# MCAN_MCAN_CORE_20701000h register map
Vendor: Texas Instruments
Peripheral module from a debugger description file (folder am62D).
Registers are 32-bit, access not given, reset 0x0 unless marked. A register's access mark holds for its fields unless they carry their own. Offsets are as the file gives them; lines under a group give offsets from that group; [hi:lo] are bit positions; {n}, {i} and the like mark numbered series; 'fields as' and 'values as' point back to an identical list; <NAME> marks a mode.

## mcan_core
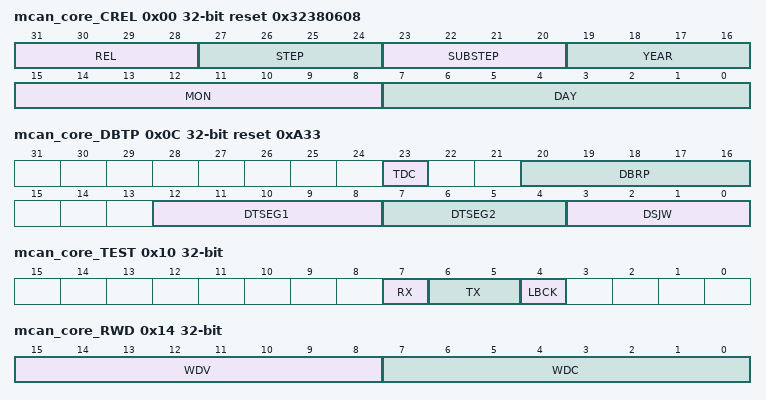
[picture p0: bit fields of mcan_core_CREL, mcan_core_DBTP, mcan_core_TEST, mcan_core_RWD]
0x00 mcan_core_CREL ro reset 0x32380608 — Release dependent constant (version + date)
  [31:28] REL — Core Release One digit, BCD-coded. Reset Source: hsrst_n
  [27:24] STEP — Step of Core Release One digit, BCD-coded. Reset Source: hsrst_n
  [23:20] SUBSTEP — Sub-step of Core Release One digit, BCD-coded. Reset Source: hsrst_n
  [19:16] YEAR — Time Stamp Year One digit, BCD-coded. Reset Source: hsrst_n
  [15:8] MON — Time Stamp Month Two digits, BCD-coded. Reset Source: hsrst_n
  [7:0] DAY — Time Stamp Day Two digits, BCD-coded. Reset Source: hsrst_n
0x04 mcan_core_ENDN ro reset 0x87654321 — Constant '0x8765 4321'
  [31:0] ETV — Endianness Test Value The endianness test value is 8765 4321h. Reset Source: hsrst_n
0x08 mcan_core_CUST reset not defined — Optional customer-specific register
0x0C mcan_core_DBTP rw reset 0xA33 — Configuration of data phase bit timing, transmitter delay compensation enable
  [23] TDC — Transmitter Delay Compensation 0h Transmitter Delay Compensation disabled1h Transmitter Delay Compensation enabled
  [20:16] DBRP — Data Baud Rate Prescaler The value by which the oscillator frequency is divided for generating the bit time quanta. The bit time is built up from a multiple of this quanta. Valid values for the Baud Rate Prescaler are 0 to 31 (0h-1Fh). The actual interpretation by the hardware of this value is such that one more than the value programmed here is used. Reset Source: hsrst_n
  [12:8] DTSEG1 — Data time segment before sample point Valid values are 0 to 31 (0h-1Fh). The actual interpretation by the hardware of this value is such that one more than the programmed value is used. Reset Source: hsrst_n
  [7:4] DTSEG2 — Data time segment after sample point Valid values are 0 to 15 (0h-Fh). The actual interpretation by the hardware of this value is such that one more than the programmed value is used. Reset Source: hsrst_n
  [3:0] DSJW — Data (Re)Synchronization Jump Width Valid values are 0 to 15 (0h-Fh). The actual interpretation by the hardware of this value is such that one more than the value programmed here is used. Reset Source: hsrst_n
0x10 mcan_core_TEST access per field — Test mode selection
  [7] RX ro — Receive Pin Monitors the actual value of the MCAN RX pin 0h The CAN bus is dominant (MCAN RX = 0h)1h The CAN bus is recessive (MCAN RX = 1h)
  [6:5] TX rw — Control of Transmit Pin 0h Reset value, the MCAN TX pin controlled by the CAN Core, updated at the end of the CAN bit time1h Sample Point can be monitored at the MCAN TX pin2h Dominant (0) level at the MCAN TX pin3h Recessive (1) at the MCAN TX pin
  [4] LBCK rw — Loopback Mode 0h Reset value, Loopback Mode is disabled1h Loopback Mode is enabled (see Test Modes)
0x14 mcan_core_RWD access per field — Monitors the READY output of the Message RAM
  [15:8] WDV ro — Watchdog Value Actual Message RAM Watchdog Counter Value. Reset Source: hsrst_n
  [7:0] WDC rw — Watchdog Configuration Start value of the Message RAM Watchdog Counter. With the reset value of 0h the counter is disabled. Reset Source: hsrst_n
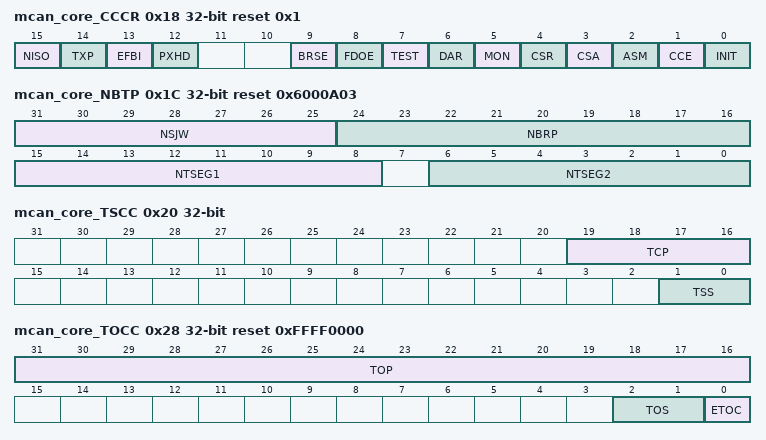
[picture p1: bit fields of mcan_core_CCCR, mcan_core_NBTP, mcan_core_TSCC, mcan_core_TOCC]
0x18 mcan_core_CCCR access per field reset 0x1 — Operation mode configuration
  [15] NISO rw — Non ISO Operation 0h CAN FD frame format according to ISO 11898-1:2015.1h CAN FD frame format according to Bosch CAN FD Specification 1.0.
  [14] TXP rw — Transmit Pause If this bit is set, the MCAN module pauses for two CAN bit times before starting the next transmission after itself has successfully transmitted a frame (see Tx Handling) . 0h Transmit pause disabled1h Transmit pause enabled
  [13] EFBI rw — Edge Filtering during Bus Integration 0h Edge filtering disabled1h Two consecutive dominant tq required to detect an edge for hard synchronization
  [12] PXHD rw — Protocol Exception Handling DisableNote: When protocol exception handling is disabled, the MCAN module will transmit an error frame when it detects a protocol exception condition. 0h Protocol exception handling enabled1h Protocol exception handling disabled
  [9] BRSE rw — Bit Rate Switch EnableNote: When CAN FD operation is disabled the MCAN_CCCR[8] FDOE = 0h 0h Bit rate switching for transmissions disabled1h Bit rate switching for transmissions enabled
  [8] FDOE rw — FD Operation Enable 0h FD operation disabled1h FD operation enabled
  [7] TEST rw — Test Mode Enable 0h Normal operation. The MCAN_TEST register holds reset values.1h Test Mode. Write access to the MCAN_TEST register enabled.
  [6] DAR rw — Disable Automatic Retransmission 0h Automatic retransmission of messages not transmitted successfully enabled1h Automatic retransmission disabled
  [5] MON rw — Bus Monitoring Mode The MCAN_CCCR[5] MON bit can only be set by the Host CPU when both MCAN_CCCR[1] CCE and MCAN_CCCR[0] INIT bits are set to 1. The bit can be reset by the Host CPU at any time. 0h Bus Monitoring Mode is disabled1h Bus Monitoring Mode is enabled
  [4] CSR rw — Clock Stop Request 0h No clock stop is requested1h Clock stop requested. When clock stop is requested, first the MCAN_CCCR[0] INIT bit and then the MCAN_CCCR[3] CSA bit will be set after all pending transfer requests have been completed and the CAN bus reached idle.
  [3] CSA ro — Clock Stop Acknowledge 0h No clock stop acknowledged1h The MCAN module may be set in power down by stopping MCAN interface clock and MCAN functional clock
  [2] ASM rw — Restricted Operation Mode The MCAN_CCCR[2] ASM bit can only be set by the Host CPU when both MCAN_CCCR[1] CCE and MCAN_CCCR[0] INIT bits are set to 1. The bit can be reset by the Host CPU at any time. For a description of the Restricted Operation Mode, see Restricted Operation Mode. 0h Normal CAN operation1h Restricted Operation Mode active
  [1] CCE rw — Configuration Change Enable 0h The Host CPU has no write access to the protected configuration registers1h The Host CPU has write access to the protected configuration registers (while the MCAN_CCCR[0] INIT = 1h)
  [0] INIT rw — InitializationNote: Due to the synchronization mechanism between the two clock domains, there may be a delay until the value written to the MCAN_CCCR[0] INIT bit can be read back. Therefore the software has to assure that the previous value written to the MCAN_CCCR[0] INIT bit has been accepted by Reading the MCAN_CCCR[0] INIT bit before setting the MCAN_CCCR[0] INIT bit to a new value. 0h Normal Operation1h Initialization is started
0x1C mcan_core_NBTP rw reset 0x6000A03 — Configuration of arbitration phase bit timing
  [31:25] NSJW — Nominal (Re)Synchronization Jump Width Valid values are 0 to 127 (0h-7Fh). The actual interpretation by the hardware of this value is such that one more than the value programmed here is used. Reset Source: hsrst_n
  [24:16] NBRP — Nominal Baud Rate Prescaler The value by which the oscillator frequency is divided for generating the bit time quanta. The bit time is built up from a multiple of this quanta. Valid values for the Baud Rate Prescaler are 0 to 511 (0h-1FFh). The actual interpretation by the hardware of this value is such that one more than the value programmed here is used. Reset Source: hsrst_n
  [15:8] NTSEG1 — Nominal Time segment before sample point Valid values are 1 to 255 (1h-FFh). The actual interpretation by the hardware of this value is such that one more than the programmed value is used. Reset Source: hsrst_n
  [6:0] NTSEG2 — Nominal Time segment after sample point Valid values are 0 to 127 (0h-7Fh). The actual interpretation by the hardware of this value is such that one more than the programmed value is used. Note: With a CAN clock (MCAN functional clock) of 8 MHz, the reset value of 0600 0A03h configures the MCAN module for a bit rate of 500 kbit/s. Reset Source: hsrst_n
0x20 mcan_core_TSCC rw — Timestamp counter prescaler setting, selection of internal/external timestamp vector
  [19:16] TCP — Timestamp Counter Prescaler Configures the timestamp and timeout counters time unit in multiples of CAN bit times [1-16 (0h-Fh)]. The actual interpretation by the hardware of this value is such that one more than the value programmed here is used. Note: With CAN FD an external counter is required for timestamp generation (MCAN_TSCC[1-0] TSS = 2h) Reset Source: hsrst_n
  [1:0] TSS — Timestamp Select 0h Timestamp counter value always 0h1h Timestamp counter value incremented according to the MCAN_TSCC[19-16] TCP field2h External timestamp counter value used3h Same as 0h
0x24 mcan_core_TSCV — Read/reset timestamp counter
  [15:0] TSC — Timestamp Counter The internal/external Timestamp Counter value is captured on start of frame (both Rx and Tx). When the MCAN_TSCC[1-0] TSS = 1h, the Timestamp Counter is incremented in multiples of CAN bit times [1-16] depending on the configuration of the MCAN_TSCC[19-16] TCP field. A wrap around sets interrupt flag MCAN_IR[16] TSW. Write access resets the counter to zero. When the MCAN_TSCC[1-0] TSS = 2h, the MCAN_TSCV[15-0] TSC field reflects the external Timestamp Counter value. A write access has no impact. Note: A 'wrap around' is a change of the Timestamp Counter value from non-zero to zero not caused by write access to the MCAN_TSCV register. Reset Source: hsrst_n (access R/WTC)
0x28 mcan_core_TOCC rw reset 0xFFFF0000 — Configuration of timeout period, selection of timeout counter operation mode
  [31:16] TOP — Timeout Period Start value of the Timeout Counter (down-counter). Configures the Timeout Period. Reset Source: hsrst_n
  [2:1] TOS — Timeout Select When operating in Continuous mode, a write to the MCAN_TOCV[15-0] TOC field presets the counter to the value configured by the MCAN_TOCC[31-16] TOP field and continues down-counting. When the Timeout Counter is controlled by one of the FIFOs, an empty FIFO presets the counter to the value configured by the MCAN_TOCC[31-16] TOP field. Down-counting is started when the first FIFO element is stored. 0h Continuous operation1h Timeout controlled by Tx Event FIFO2h Timeout controlled by Rx FIFO 03h Timeout controlled by Rx FIFO 1
  [0] ETOC — Enable Timeout Counter 0h Timeout Counter disabled1h Timeout Counter enabled
0x2C mcan_core_TOCV reset 0xFFFF — Read/reset timeout counter
  [15:0] TOC — Timeout Counter The Timeout Counter is decremented in multiples of CAN bit times [1-16] depending on the configuration of the MCAN_TSCC[19-16] TCP field. When decremented to zero, interrupt flag MCAN_IR[18] TOO is set and the Timeout Counter is stopped. Start and reset/ restart conditions are configured via the MCAN_TOCC[2-1] TOS field. Reset Source: hsrst_n (access R/WTC)
0x30 mcan_core_reserved00 reset not defined — Reserved field
0x34 mcan_core_reserved11 reset not defined — Reserved field
0x38 mcan_core_reserved22 reset not defined — Reserved field
0x3C mcan_core_reserved33 reset not defined — Reserved field
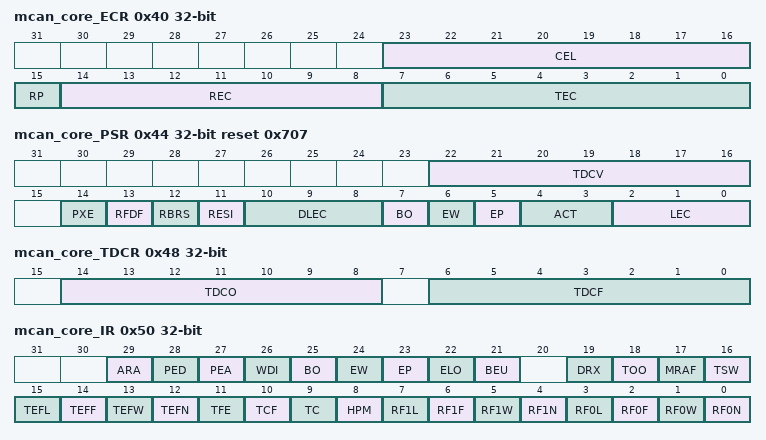
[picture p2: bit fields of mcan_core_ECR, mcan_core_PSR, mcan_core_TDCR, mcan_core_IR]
0x40 mcan_core_ECR ro — State of Rx/Tx Error Counter, CAN Error Logging
  [23:16] CEL — CAN Error Logging The counter is incremented each time when a CAN protocol error causes the Transmit Error Counter or the Receive Error Counter to be incremented. It is reset by read access to the MCAN_ECR[23-16] CEL field. The counter stops at FFh; the next increment of the MCAN_ECR[7-0] TEC or MCAN_ECR[14-8] REC fields sets interrupt flag MCAN_IR[22] ELO. Reset Source: hsrst_n
  [15] RP — Receive Error Passive 0h The Receive Error Counter is below the error passive level of 1281h The Receive Error Counter has reached the error passive level of 128
  [14:8] REC — Receive Error Counter Actual state of the Receive Error Counter, values between 0 and 127. Reset Source: hsrst_n
  [7:0] TEC — Transmit Error Counter Actual state of the Transmit Error Counter, values between 0 and 255. Note: When the MCAN_CCCR[2] ASM bit is set, the CAN protocol controller does not increment the MCAN_ECR[7-0] TEC and MCAN_ECR[14-8] REC fields when a CAN protocol error is detected, but the MCAN_ECR[23-16] CEL field is still incremented. Reset Source: hsrst_n
0x44 mcan_core_PSR ro reset 0x707 — CAN protocol controller status, transmitter delay compensation value
  [22:16] TDCV — Transmitter Delay Compensation Value Position of the secondary sample point, defined by the sum of the measured delay from the MCAN TX to MCAN RX pins and the MCAN_TDCR[14-8] TDCO field. The SSP position is, in the data phase, the number of mtq between the start of the transmitted bit and the secondary sample point. Valid values are 0 to 127 mtq (0h-7Fh). Reset Source: hsrst_n
  [14] PXE — Protocol Exception Event 0h No protocol exception event occurred since last read access1h Protocol exception event occurred
  [13] RFDF — Received a CAN FD Message This bit is set independent of acceptance filtering. 0h Since this bit was reset by the Host CPU, no CAN FD message has been received1h Message in CAN FD format with FDF flag set has been received
  [12] RBRS — BRS flag of last received CAN FD Message This bit is set together with the MCAN_PSR[13] RFDF bit, independent of acceptance filtering. 0h Last received CAN FD message did not have its BRS flag set1h Last received CAN FD message had its BRS flag set
  [11] RESI — ESI flag of last received CAN FD Message This bit is set together with the MCAN_PSR[13] RFDF bit, independent of acceptance filtering. 0h Last received CAN FD message did not have its ESI flag set1h Last received CAN FD message had its ESI flag set
  [10:8] DLEC — Data Phase Last Error Code Type of last error that occurred in the data phase of a CAN FD format frame with its BRS flag set. Coding is the same as for the MCAN_PSR[2-0] LEC field. This field will be cleared to zero when a CAN FD format frame with its BRS flag set has been transferred (reception or transmission) without error. Reset Source: hsrst_n
  [7] BO — Bus_Off Status 0h The MCAN module is not Bus_Off1h The MCAN module is in Bus_Off state
  [6] EW — Warning Status 0h Both error counters are below the Error_Warning limit of 961h At least one of error counter has reached the Error_Warning limit of 96
  [5] EP — Error Passive 0h The MCAN module is in the Error_Active state. It normally takes part in bus communication and sends an active error flag when an error has been detected1h The MCAN module is in the Error_Passive state
  [4:3] ACT — Activity Monitors the module's CAN communication state.Note: ACT is set to 0h by a Protocol Exception Event. 0h Synchronizing - node is synchronizing on CAN communication1h Idle - node is neither receiver nor transmitter2h Receiver - node is operating as receiver3h Transmitter - node is operating as transmitter
  [2:0] LEC — Last Error Code The MCAN_PSR[2-0] LEC field indicates the type of the last error to occur on the CAN bus. This field will be cleared to 0h when a message has been transferred (reception or transmission) without error.Note: When a frame in CAN FD format has reached the data phase with BRS flag set, the next CAN event (error or valid frame) will be shown in the MCAN_PSR[10-8] DLEC field instead of the MCAN_PSR[2-0] LEC field. An error in a fixed stuff bit of a CAN FD CRC sequence will be shown as a Form Error, not Stuff Error. 0h No Error: No error occurred since the MCAN_PSR[2-0] LEC field has been reset by successful reception or transmission.1h Stuff Error: More than 5 equal bits in a sequence have occurred in a part of a received message where this is not allowed.2h Form Error: A fixed format part of a received frame has the wrong format.3h AckError: The message transmitted by the MCAN module was not acknowledged by another node.4h Bit1Error: During the transmission of a message (with the exception of the arbitration field), the device wanted to send a recessive level (bit of logical value 1), but the monitored bus value was dominant.5h Bit0Error: During the transmission of a message (or acknowledge bit, or active error flag, or overload flag), the device wanted to send a dominant level (data or identifier bit logical value 0), but the monitored bus value was recessive. During Bus_Off recovery this status is set each time a sequence of 11 recessive bits has been monitored. This enables the Host CPU to monitor the proceeding of the Bus_Off recovery sequence (indicating the bus is not stuck at dominant or continuously disturbed).6h CRCError: The CRC check sum of a received message was incorrect. The CRC of an incom- ing message does not match with the CRC calculated from the received data.7h NoChange: Any read access to the Protocol Status Register re-initializes the MCAN_PSR[2-0] LEC field to 7h. When the MCAN_PSR[2-0] LEC field shows the value 7h, no CAN bus event was detected since the last Host CPU read access to the Protocol Status Register.
0x48 mcan_core_TDCR rw — configuration of transmitter delay compensation offset and filter window length
  [14:8] TDCO — Transmitter Delay Compensation Offset Offset value defining the distance between the measured delay from the MCAN RX and MCAN TX pins and the secondary sample point. Valid values are 0 to 127 mtq (0h-7Fh). Reset Source: hsrst_n
  [6:0] TDCF — Transmitter Delay Compensation Filter Window Length Defines the minimum value for the SSP position, dominant edges on the MCAN RX pin that would result in an earlier SSP position are ignored for transmitter delay measure-ment. The feature is enabled when the MCAN_TDCR[6-0] TDCF field is configured to a value greater than the MCAN_TDCR[14-8] TDCO field. Valid values are 0 to 127 mtq (0h-7Fh). Reset Source: hsrst_n
0x4C mcan_core_reserved44 reset not defined — Reserved field
0x50 mcan_core_IR — Interrupt flags
  [29] ARA — Access to Reserved Address 0h No access to reserved address occurred1h Access to reserved address occurred (access R/W1TC)
  [28] PED — Protocol Error in Data Phase 0h No protocol error in data phase1h Protocol error in data phase detected (MCAN_PSR[10-8] DLEC != 0.7) (access R/W1TC)
  [27] PEA — Protocol Error in Arbitration Phase 0h No protocol error in arbitration phase1h Protocol error in arbitration phase detected (MCAN_PSR[2-0] LEC != 0.7) (access R/W1TC)
  [26] WDI — Watchdog Interrupt 0h No Message RAM Watchdog event occurred1h Message RAM Watchdog event due to missing READY (access R/W1TC)
  [25] BO — Bus_Off Status 0h Bus_Off status unchanged1h Bus_Off status changed (access R/W1TC)
  [24] EW — Warning Status 0h Error_Warning status unchanged1h Error_Warning status changed (access R/W1TC)
  [23] EP — Error Passive 0h Error_Passive status unchanged1h Error_Passive status changed (access R/W1TC)
  [22] ELO — Error Logging Overflow 0h CAN Error Logging Counter did not overflow1h Overflow of CAN Error Logging Counter occurred (access R/W1TC)
  [21] BEU — Bit Error Uncorrected Message RAM bit error detected, uncorrected. Controlled by input signal generated by parity/ECC logic attached to the Message RAM. An uncorrected Message RAM bit error sets the MCAN_CCCR[0] INIT bit to 1. This is done to avoid transmission of corrupted data. 0h No bit error detected when reading from Message RAM1h Bit error detected, uncorrected (example: parity logic) (access R/W1TC)
  [19] DRX — Message stored to Dedicated Rx Buffer The flag is set whenever a received message has been stored into a dedicated Rx Buffer. 0h No Rx Buffer updated1h At least one received message stored into an Rx Buffer (access R/W1TC)
  [18] TOO — Timeout Occurred 0h No timeout1h Timeout reached (access R/W1TC)
  [17] MRAF — Message RAM Access Failure The flag is set, when the Rx Handler: a) has not completed acceptance filtering or storage of an accepted message until the arbitration field of the following message has been received. In this case acceptance filtering or message storage is aborted and the Rx Handler starts processing of the following message. b) was not able to write a message to the Message RAM. In this case message storage is aborted. In both cases the FIFO put index is not updated respectively the New Data flag for a dedicated Rx Buffer is not set, a partly stored message is overwritten when the next message is stored to this location. The flag is also set when the Tx Handler was not able to read a message from the Message RAM in time. In this case message transmission is aborted. In case of a Tx Handler access failure the MCAN module is switched into Restricted Operation Mode (see Restricted Operation Mode). To leave Restricted Operation Mode, the Host CPU has to reset the MCAN_CCCR[2] ASM bit. 0h No Message RAM access failure occurred1h Message RAM access failure occurred (access R/W1TC)
  [16] TSW — Timestamp Wraparound 0h No timestamp counter wrap-around1h Timestamp counter wrapped around (access R/W1TC)
  [15] TEFL — Tx Event FIFO Element Lost 0h No Tx Event FIFO element lost1h Tx Event FIFO element lost, also set after write attempt to Tx Event FIFO of size zero (access R/W1TC)
  [14] TEFF — Tx Event FIFO Full 0h Tx Event FIFO not full1h Tx Event FIFO full (access R/W1TC)
  [13] TEFW — Tx Event FIFO Watermark Reached 0h Tx Event FIFO fill level below watermark1h Tx Event FIFO fill level reached watermark (access R/W1TC)
  [12] TEFN — Tx Event FIFO New Entry 0h Tx Event FIFO unchanged1h Tx Handler wrote Tx Event FIFO element (access R/W1TC)
  [11] TFE — Tx FIFO Empty 0h Tx FIFO non-empty1h Tx FIFO empty (access R/W1TC)
  [10] TCF — Transmission Cancellation Finished 0h No transmission cancellation finished1h Transmission cancellation finished (access R/W1TC)
  [9] TC — Transmission Completed 0h No transmission completed1h Transmission completed (access R/W1TC)
  [8] HPM — High Priority Message 0h No high priority message received1h High priority message received (access R/W1TC)
  [7] RF1L — Rx FIFO 1 Message Lost 0h No Rx FIFO 1 message lost1h Rx FIFO 1 message lost, also set after write attempt to Rx FIFO 1 of size zero (access R/W1TC)
  [6] RF1F — Rx FIFO 1 Full 0h Rx FIFO 1 not full1h Rx FIFO 1 full (access R/W1TC)
  [5] RF1W — Rx FIFO 1 Watermark Reached 0h Rx FIFO 1 fill level below watermark1h Rx FIFO 1 fill level reached watermark (access R/W1TC)
  [4] RF1N — Rx FIFO 1 New Message 0h No new message written to Rx FIFO 11h New message written to Rx FIFO 1 (access R/W1TC)
  [3] RF0L — Rx FIFO 0 Message Lost 0h No Rx FIFO 0 message lost1h Rx FIFO 0 message lost, also set after write attempt to Rx FIFO 0 of size zero (access R/W1TC)
  [2] RF0F — Rx FIFO 0 Full 0h Rx FIFO 0 not full1h Rx FIFO 0 full (access R/W1TC)
  [1] RF0W — Rx FIFO 0 Watermark Reached 0h Rx FIFO 0 fill level below watermark1h Rx FIFO 0 fill level reached watermark (access R/W1TC)
  [0] RF0N — Rx FIFO 0 New Message 0h No new message written to Rx FIFO 01h New message written to Rx FIFO 0 (access R/W1TC)
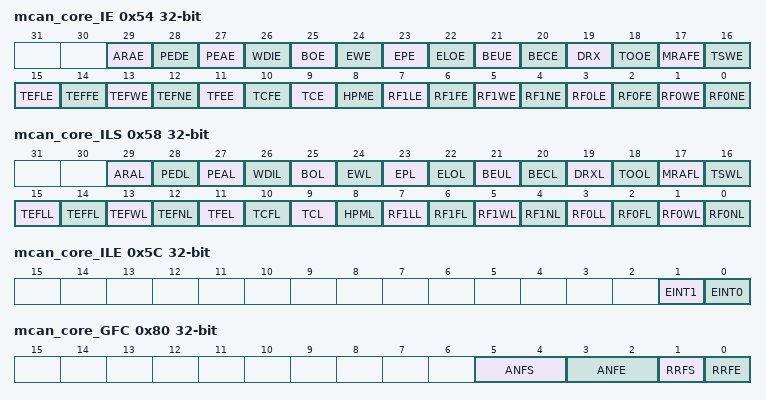
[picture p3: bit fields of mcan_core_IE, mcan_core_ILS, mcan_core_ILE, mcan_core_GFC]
0x54 mcan_core_IE rw — Interrupt enable/disable
  [29] ARAE — Access to Reserved Address Enable 0h Interrupt disabled1h Interrupt enabled
  [28] PEDE — Protocol Error in Data Phase Enable 0h Interrupt disabled1h Interrupt enabled
  [27] PEAE — Protocol Error in Arbitration Phase Enable 0h Interrupt disabled1h Interrupt enabled
  [26] WDIE — Watchdog Interrupt Enable 0h Interrupt disabled1h Interrupt enabled
  [25] BOE — Bus_Off Status Interrupt Enable 0h Interrupt disabled1h Interrupt enabled
  [24] EWE — Warning Status Interrupt Enable 0h Interrupt disabled1h Interrupt enabled
  [23] EPE — Error Passive Interrupt Enable 0h Interrupt disabled1h Interrupt enabled
  [22] ELOE — Error Logging Overflow Interrupt Enable 0h Interrupt disabled1h Interrupt enabled
  [21] BEUE — Bit Error Uncorrected Interrupt Enable 0h Interrupt disabled1h Interrupt enabled
  [20] BECE — Bit Error Corrected Interrupt Enable 0h Interrupt disabled1h Interrupt enabled
  [19] DRX — Message stored to Dedicated Rx Buffer Interrupt Enable Reset Source: hsrst_n
  [18] TOOE — Timeout Occurred Interrupt Enable 0h Interrupt disabled1h Interrupt enabled
  [17] MRAFE — Message RAM Access Failure Interrupt Enable 0h Interrupt disabled1h Interrupt enabled
  [16] TSWE — Timestamp Wraparound Interrupt Enable 0h Interrupt disabled1h Interrupt enabled
  [15] TEFLE — Tx Event FIFO Event Lost Interrupt Enable 0h Interrupt disabled1h Interrupt enabled
  [14] TEFFE — Tx Event FIFO Full Interrupt Enable 0h Interrupt disabled1h Interrupt enabled
  [13] TEFWE — Tx Event FIFO Watermark Reached Interrupt Enable 0h Interrupt disabled1h Interrupt enabled
  [12] TEFNE — Tx Event FIFO New Entry Interrupt Enable 0h Interrupt disabled1h Interrupt enabled
  [11] TFEE — Tx FIFO Empty Interrupt Enable 0h Interrupt disabled1h Interrupt enabled
  [10] TCFE — Transmission Cancellation Finished Interrupt Enable 0h Interrupt disabled1h Interrupt enabled
  [9] TCE — Transmission Completed Interrupt Enable 0h Interrupt disabled1h Interrupt enabled
  [8] HPME — High Priority Message Interrupt Enable 0h Interrupt disabled1h Interrupt enabled
  [7] RF1LE — Rx FIFO 1 Message Lost Interrupt Enable 0h Interrupt disabled1h Interrupt enabled
  [6] RF1FE — Rx FIFO 1 Full Interrupt Enable 0h Interrupt disabled1h Interrupt enabled
  [5] RF1WE — Rx FIFO 1 Watermark Reached Interrupt Enable 0h Interrupt disabled1h Interrupt enabled
  [4] RF1NE — Rx FIFO 1 New Message Interrupt Enable 0h Interrupt disabled1h Interrupt enabled
  [3] RF0LE — Rx FIFO 0 Message Lost Interrupt Enable 0h Interrupt disabled1h Interrupt enabled
  [2] RF0FE — Rx FIFO 0 Full Interrupt Enable 0h Interrupt disabled1h Interrupt enabled
  [1] RF0WE — Rx FIFO 0 Watermark Reached Interrupt Enable 0h Interrupt disabled1h Interrupt enabled
  [0] RF0NE — Rx FIFO 0 New Message Interrupt Enable 0h Interrupt disabled1h Interrupt enabled
0x58 mcan_core_ILS rw — Interrupt line select (m_can_int0 or m_can_int1)
  [29] ARAL — Access to Reserved Address Line 0h Interrupt assigned to interrupt line INT01h Interrupt assigned to interrupt line INT1
  [28] PEDL — Protocol Error in Data Phase Line 0h Interrupt assigned to interrupt line INT01h Interrupt assigned to interrupt line INT1
  [27] PEAL — Protocol Error in Arbitration Phase Line 0h Interrupt assigned to interrupt line INT01h Interrupt assigned to interrupt line INT1
  [26] WDIL — Watchdog Interrupt Line 0h Interrupt assigned to interrupt line INT01h Interrupt assigned to interrupt line INT1
  [25] BOL — Bus_Off Status Interrupt Line 0h Interrupt assigned to interrupt line INT01h Interrupt assigned to interrupt line INT1
  [24] EWL — Warning Status Interrupt Line 0h Interrupt assigned to interrupt line INT01h Interrupt assigned to interrupt line INT1
  [23] EPL — Error Passive Interrupt Line 0h Interrupt assigned to interrupt line INT01h Interrupt assigned to interrupt line INT1
  [22] ELOL — Error Logging Overflow Interrupt Line 0h Interrupt assigned to interrupt line INT01h Interrupt assigned to interrupt line INT1
  [21] BEUL — Bit Error Uncorrected Interrupt Line 0h Interrupt assigned to interrupt line INT01h Interrupt assigned to interrupt line INT1
  [20] BECL — Bit Error Corrected Interrupt Line 0h Interrupt assigned to interrupt line INT01h Interrupt assigned to interrupt line INT1
  [19] DRXL — Message stored to Dedicated Rx Buffer Interrupt Line 0h Interrupt assigned to interrupt line INT01h Interrupt assigned to interrupt line INT1
  [18] TOOL — Timeout Occurred Interrupt Line 0h Interrupt assigned to interrupt line INT01h Interrupt assigned to interrupt line INT1
  [17] MRAFL — Message RAM Access Failure Interrupt Line 0h Interrupt assigned to interrupt line INT01h Interrupt assigned to interrupt line INT1
  [16] TSWL — Timestamp Wraparound Interrupt Line 0h Interrupt assigned to interrupt line INT01h Interrupt assigned to interrupt line INT1
  [15] TEFLL — Tx Event FIFO Event Lost Interrupt Line 0h Interrupt assigned to interrupt line INT01h Interrupt assigned to interrupt line INT1
  [14] TEFFL — Tx Event FIFO Full Interrupt Line 0h Interrupt assigned to interrupt line INT01h Interrupt assigned to interrupt line INT1
  [13] TEFWL — Tx Event FIFO Watermark Reached Interrupt Line 0h Interrupt assigned to interrupt line INT01h Interrupt assigned to interrupt line INT1
  [12] TEFNL — Tx Event FIFO New Entry Interrupt Line 0h Interrupt assigned to interrupt line INT01h Interrupt assigned to interrupt line INT1
  [11] TFEL — Tx FIFO Empty Interrupt Line 0h Interrupt assigned to interrupt line INT01h Interrupt assigned to interrupt line INT1
  [10] TCFL — Transmission Cancellation Finished Interrupt Line 0h Interrupt assigned to interrupt line INT01h Interrupt assigned to interrupt line INT1
  [9] TCL — Transmission Completed Interrupt Line 0h Interrupt assigned to interrupt line INT01h Interrupt assigned to interrupt line INT1
  [8] HPML — High Priority Message Interrupt Line 0h Interrupt assigned to interrupt line INT01h Interrupt assigned to interrupt line INT1
  [7] RF1LL — Rx FIFO 1 Message Lost Interrupt Line 0h Interrupt assigned to interrupt line INT01h Interrupt assigned to interrupt line INT1
  [6] RF1FL — Rx FIFO 1 Full Interrupt Line 0h Interrupt assigned to interrupt line INT01h Interrupt assigned to interrupt line INT1
  [5] RF1WL — Rx FIFO 1 Watermark Reached Interrupt Line 0h Interrupt assigned to interrupt line INT01h Interrupt assigned to interrupt line INT1
  [4] RF1NL — Rx FIFO 1 New Message Interrupt Line 0h Interrupt assigned to interrupt line INT01h Interrupt assigned to interrupt line INT1
  [3] RF0LL — Rx FIFO 0 Message Lost Interrupt Line 0h Interrupt assigned to interrupt line INT01h Interrupt assigned to interrupt line INT1
  [2] RF0FL — Rx FIFO 0 Full Interrupt Line 0h Interrupt assigned to interrupt line INT01h Interrupt assigned to interrupt line INT1
  [1] RF0WL — Rx FIFO 0 Watermark Reached Interrupt Line 0h Interrupt assigned to interrupt line INT01h Interrupt assigned to interrupt line INT1
  [0] RF0NL — Rx FIFO 0 New Message Interrupt Line 0h Interrupt assigned to interrupt line INT01h Interrupt assigned to interrupt line INT1
0x5C mcan_core_ILE rw — Enable/disable interrupt lines m_can_int0 / m_can_int1
  [1] EINT1 — Enable Interrupt Line 1 0h Interrupt line INT1 disabled1h Interrupt line INT1 enabled
  [0] EINT0 — Enable Interrupt Line 0 0h Interrupt line INT0 disabled1h Interrupt line INT0 enabled
0x60 mcan_core_reserved55 reset not defined — Reserved field
0x64 mcan_core_reserved66 reset not defined — Reserved field
0x68 mcan_core_reserved77 reset not defined — Reserved field
0x6C mcan_core_reserved88 reset not defined — Reserved field
0x70 mcan_core_reserved99 reset not defined — Reserved field
0x74 mcan_core_reserved1010 reset not defined — Reserved field
0x78 mcan_core_reserved1111 reset not defined — Reserved field
0x7C mcan_core_reserved1212 reset not defined — Reserved field
0x80 mcan_core_GFC rw — Handling of non-matching frames and remote frames
  [5:4] ANFS — Accept Non-matching Frames Standard Defines how received messages with 11-bit IDs that do not match any element of the filter list are treated. 0h Accept in Rx FIFO 01h Accept in Rx FIFO 12h Reject3h Reject
  [3:2] ANFE — Accept Non-matching Frames Extended Defines how received messages with 29-bit IDs that do not match any element of the filter list are treated. 0h Accept in Rx FIFO 01h Accept in Rx FIFO 12h Reject3h Reject
  [1] RRFS — Reject Remote Frames Standard 0h Filter remote frames with 11-bit standard IDs1h Reject all remote frames with 11-bit standard IDs
  [0] RRFE — Reject Remote Frames Extended 0h Filter remote frames with 29-bit extended IDs1h Reject all remote frames with 29-bit extended IDs
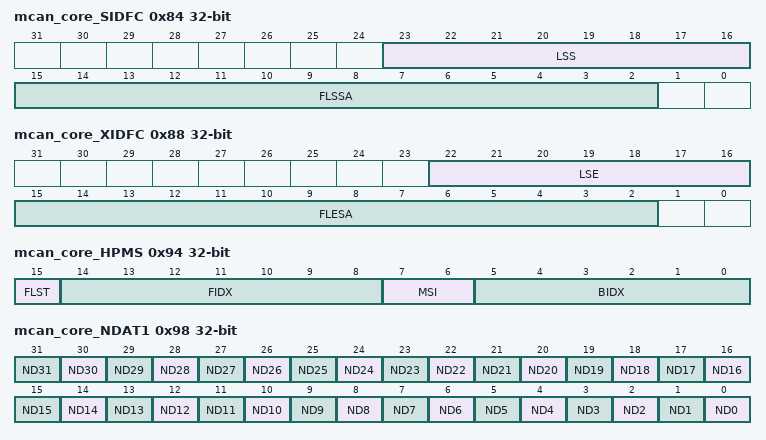
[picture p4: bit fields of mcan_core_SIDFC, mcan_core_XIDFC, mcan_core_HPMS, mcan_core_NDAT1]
0x84 mcan_core_SIDFC rw — Number of filter elements, pointer to start of filter list
  [23:16] LSS — List Size Standard 0h No standard Message ID filter1h-80 Number of standard Message ID filterh elements>80h Values greater than 128 are interpreted as 128
  [15:2] FLSSA — Filter List Standard Start Address Start address of standard Message ID filter list (32-bit word address, see Message RAM Configuration). Reset Source: hsrst_n
0x88 mcan_core_XIDFC rw — Number of filter elements, pointer to start of filter list
  [22:16] LSE — List Size Extended 0h No extended Message ID filter1h-40 Number of extended Message ID filterh elements>40h Values greater than 64 are interpreted as 64
  [15:2] FLESA — Filter List Extended Start Address Start address of extended Message ID filter list (32-bit word address, see Message RAM Configuration). Reset Source: hsrst_n
0x8C mcan_core_reserved1313 reset not defined — Reserved field
0x90 mcan_core_XIDAM rw reset 0x1FFFFFFF — 29-bit logical AND mask for J1939
  [28:0] EIDM — Extended ID Mask For acceptance filtering of extended frames the Extended ID AND Mask is ANDed with the Message ID of a received frame. Intended for masking of 29-bit IDs in SAE J1939. With the reset value of all bits set to one the mask is not active. Reset Source: hsrst_n
0x94 mcan_core_HPMS ro — Status monitoring of incoming high priority messages
  [15] FLST — Filter List Indicates the filter list of the matching filter element. 0h Standard Filter List1h Extended Filter List
  [14:8] FIDX — Filter Index Index of matching filter element. Range is 0 to MCAN_SIDFC[23-16] LSS - 1 respectively MCAN_XIDFC[22-16] LSE - 1. Reset Source: hsrst_n
  [7:6] MSI — Message Storage Indicator 0h No FIFO selected1h FIFO message lost2h Message stored in FIFO 03h Message stored in FIFO 1
  [5:0] BIDX — Buffer Index Index of Rx FIFO element to which the message was stored. Only valid when the MCAN_HPMS[7-6] MSI = 1h. Reset Source: hsrst_n
0x98 mcan_core_NDAT1 — NewDat flags of dedicated Rx buffers 0-31
  [n] ND{n} (n=0..31) — New Data 0h Rx Buffer not updated1h Rx Buffer updated from new message (access R/W1TC)
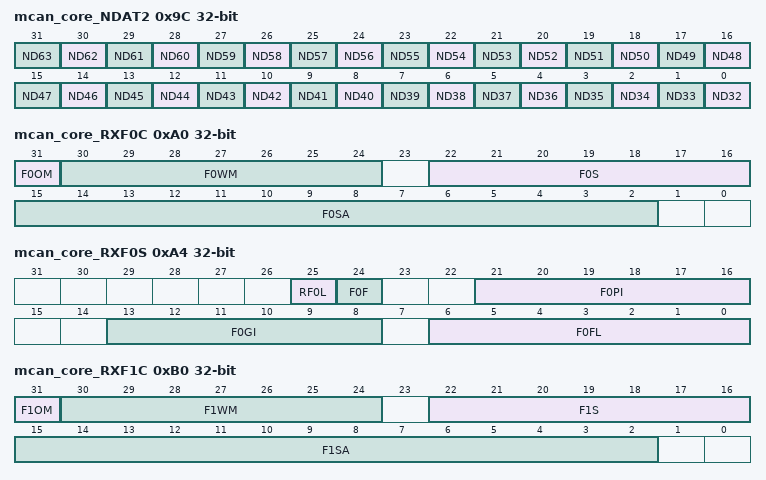
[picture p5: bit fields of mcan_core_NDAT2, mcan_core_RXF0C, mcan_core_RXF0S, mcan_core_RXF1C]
0x9C mcan_core_NDAT2 — NewDat flags of dedicated Rx buffers 32-63
  [n-32] ND{n} (n=32..63) — New Data 0h Rx Buffer not updated1h Rx Buffer updated from new message (access R/W1TC)
0xA0 mcan_core_RXF0C rw — FIFO 0 operation mode, watermark, size and start address
  [31] F0OM — FIFO 0 Operation Mode FIFO 0 can be operated in blocking or in overwrite mode (see Rx FIFOs). 0h FIFO 0 blocking mode1h FIFO 0 overwrite mode
  [30:24] F0WM — Rx FIFO 0 Watermark 0h Watermark interrupt disabled1h-40 Level for Rx FIFO 0 watermark interrupth (MCAN_IR[1] RF0W)>40h Watermark interrupt disabled
  [22:16] F0S — Rx FIFO 0 Size 0h No Rx FIFO 01h-40 Number of Rx FIFO 0 elementsh>40h Values greater than 64 are interpreted as 64 The Rx FIFO 0 elements are indexed from 0 to MCAN_RXF0C[22-16] F0S - 1.
  [15:2] F0SA — Rx FIFO 0 Start Address Start address of Rx FIFO 0 in Message RAM (32-bit word address, see Message RAM Configuration). Reset Source: hsrst_n
0xA4 mcan_core_RXF0S ro — FIFO 0 message lost/full indication, put index, get index and fill level
  [25] RF0L — Rx FIFO 0 Message Lost This bit is a copy of interrupt flag MCAN_IR[3] RF0L. When the MCAN_IR[3] RF0L flag is reset, this bit is also reset.Note: OverWriting the oldest message when the MCAN_RXF0C[31] F0OM = 1h 0h No Rx FIFO 0 message lost1h Rx FIFO 0 message lost, also set after write attempt to Rx FIFO 0 of size zero
  [24] F0F — Rx FIFO 0 Full 0h Rx FIFO 0 not full1h Rx FIFO 0 full
  [21:16] F0PI — Rx FIFO 0 Put Index Rx FIFO 0 write index pointer, range 0 to 63. Reset Source: hsrst_n
  [13:8] F0GI — Rx FIFO 0 Get Index Rx FIFO 0 read index pointer, range 0 to 63. Reset Source: hsrst_n
  [6:0] F0FL — Rx FIFO 0 Fill Level Number of elements stored in Rx FIFO 0, range 0 to 64. Reset Source: hsrst_n
0xA8 mcan_core_RXF0A rw — FIFO 0 acknowledge last index of read buffers, updates get index and fill level
  [5:0] F0AI — Rx FIFO 0 Acknowledge Index After the Host CPU has read a message or a sequence of messages from Rx FIFO 0 it has to write the buffer index of the last element read from Rx FIFO 0 to the MCAN_RXF0A[5-0] F0AI field. This will set the Rx FIFO 0 Get Index MCAN_RXF0S[13-8] F0GI field to the MCAN_RXF0A[5-0] F0AI field + 1 and update the FIFO 0 Fill Level MCAN_RXF0S[6-0] F0FL field. Reset Source: hsrst_n
0xAC mcan_core_RXBC rw — Start address of Rx buffer section
  [15:2] RBSA — Rx Buffer Start Address Configures the start address of the Rx Buffers section in the Message RAM (32-bit word address, see Message RAM Configuration). Also used to reference debug messages A, B, C. Note: Debug feature is not supported. Reset Source: hsrst_n
0xB0 mcan_core_RXF1C rw — FIFO 1 operation mode, watermark, size and start address
  [31] F1OM — FIFO 1 Operation Mode FIFO 1 can be operated in blocking or in overwrite mode (see Rx FIFOs). 0h FIFO 1 blocking mode1h FIFO 1 overwrite mode
  [30:24] F1WM — Rx FIFO 1 Watermark 0h Watermark interrupt disabled1h-40 Level for Rx FIFO 1 watermark interrupth (MCAN_IR[5] RF1W)>40h Watermark interrupt disabled
  [22:16] F1S — Rx FIFO 1 Size 0h No Rx FIFO 11h-40 Number of Rx FIFO 1 elementsh>40h Values greater than 64 are interpreted as 64 The Rx FIFO 1 elements are indexed from 0 to MCAN_RXF1C[22-16] F1S - 1.
  [15:2] F1SA — Rx FIFO 1 Start Address Start address of Rx FIFO 1 in Message RAM (32-bit word address, see Message RAM Configuration). Reset Source: hsrst_n
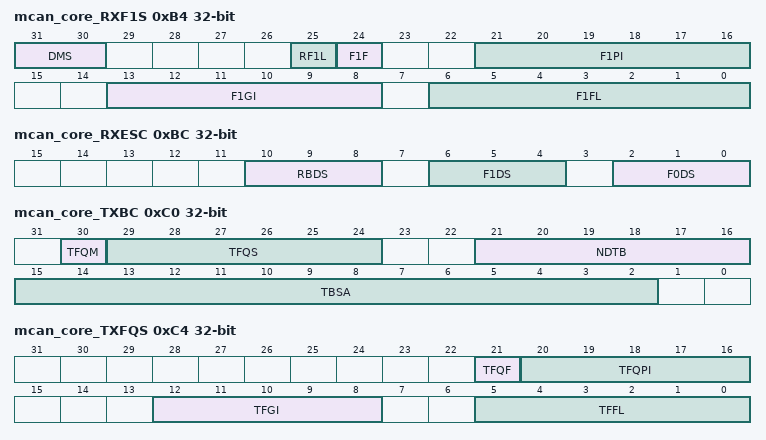
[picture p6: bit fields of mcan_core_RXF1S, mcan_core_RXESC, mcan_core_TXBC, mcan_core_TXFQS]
0xB4 mcan_core_RXF1S ro — FIFO 1 message lost/full indication, put index, get index and fill level
  [31:30] DMS — Debug Message StatusNote: Debug feature is not supported. 0h Idle state, wait for reception of debug messages, DMA request is cleared1h Debug message A received2h Debug messages A, B received3h Debug messages A, B, C received, DMA request is set
  [25] RF1L — Rx FIFO 1 Message Lost This bit is a copy of interrupt flag MCAN_IR[7] RF1L. When the MCAN_IR[7] RF1L flag is reset, this bit is also reset.Note: OverWriting the oldest message when the MCAN_RXF1C[31] F1OM = 1h 0h No Rx FIFO 1 message lost1h Rx FIFO 1 message lost, also set after write attempt to Rx FIFO 1 of size zero
  [24] F1F — Rx FIFO 1 Full 0h Rx FIFO 1 not full1h Rx FIFO 1 full
  [21:16] F1PI — Rx FIFO 1 Put Index Rx FIFO 1 write index pointer, range 0 to 63. Reset Source: hsrst_n
  [13:8] F1GI — Rx FIFO 1 Get Index Rx FIFO 1 read index pointer, range 0 to 63. Reset Source: hsrst_n
  [6:0] F1FL — Rx FIFO 1 Fill Level Number of elements stored in Rx FIFO 1, range 0 to 64. Reset Source: hsrst_n
0xB8 mcan_core_RXF1A rw — FIFO 1 acknowledge last index of read buffers, updates get index and fill level
  [5:0] F1AI — Rx FIFO 1 Acknowledge Index After the Host CPU has read a message or a sequence of messages from Rx FIFO 1 it has to write the buffer index of the last element read from Rx FIFO 1 to the MCAN_RXF1A[5-0] F1AI field. This will set the Rx FIFO 1 Get Index MCAN_RXF1S[13-8] F1GI field to the MCAN_RXF1A[5-0] F1AI field + 1 and update the FIFO 1 Fill Level MCAN_RXF1S[6-0] F1FL field. Reset Source: hsrst_n
0xBC mcan_core_RXESC rw — Configure data field size for storage of accepted frames
  [10:8] RBDS — Rx Buffer Data Field Size 0h 8 byte data field1h 12 byte data field2h 16 byte data field3h 20 byte data field4h 24 byte data field5h 32 byte data field6h 48 byte data field7h 64 byte data field
  [6:4] F1DS — Rx FIFO 1 Data Field Size 0h 8 byte data field1h 12 byte data field2h 16 byte data field3h 20 byte data field4h 24 byte data field5h 32 byte data field6h 48 byte data field7h 64 byte data field
  [2:0] F0DS — Rx FIFO 0 Data Field SizeNote: In case the data field size of an accepted CAN frame exceeds the data field size configured for the matching Rx Buffer or Rx FIFO, only the number of bytes as configured by the MCAN_RXESC register are stored to the Rx Buffer respectively Rx FIFO element. The rest of the frame's data field is ignored. 0h 8 byte data field1h 12 byte data field2h 16 byte data field3h 20 byte data field4h 24 byte data field5h 32 byte data field6h 48 byte data field7h 64 byte data field
0xC0 mcan_core_TXBC rw — Configure Tx FIFO/Queue mode, Tx FIFO/Queue size, number of dedicated Tx buffers, Tx buffer start address
  [30] TFQM — Tx FIFO/Queue Mode 0h Tx FIFO operation1h Tx Queue operation
  [29:24] TFQS — Transmit FIFO/Queue Size 0h No Tx FIFO/Queue1h-20 Number of Tx Buffers used for Tx FIFO/Queueh>20h Values greater than 32 are interpreted as 32
  [21:16] NDTB — Number of Dedicated Transmit Buffers 0h No Dedicated Tx Buffers1h-20 Number of Dedicated Tx Buffersh>20h Values greater than 32 are interpreted as 32
  [15:2] TBSA — Tx Buffers Start Address Start address of Tx Buffers section in Message RAM (32-bit word address, see Message RAM Configuration). Note: Be aware that the sum of the MCAN_TXBC[29-24] TFQS and MCAN_TXBC[21-16] NDTB fields may be not greater than 32. There is no check for erroneous configurations. The Tx Buffers section in the Message RAM starts with the dedicated Tx Buffers. Reset Source: hsrst_n
0xC4 mcan_core_TXFQS ro — Tx FIFO/Queue full indication and put index, Tx FIFO get index and fill level
  [21] TFQF — Tx FIFO/Queue Full 0h Tx FIFO/Queue not full1h Tx FIFO/Queue full
  [20:16] TFQPI — Tx FIFO/Queue Put Index Tx FIFO/Queue write index pointer, range 0 to 31. Reset Source: hsrst_n
  [12:8] TFGI — Tx FIFO Get Index Tx FIFO read index pointer, range 0 to 31. Read as zero when Tx Queue operation is configured (MCAN_TXBC[30] TFQM = 1h). Reset Source: hsrst_n
  [5:0] TFFL — Tx FIFO Free Level Number of consecutive free Tx FIFO elements starting from the MCAN_TXFQS[12-8] TFGI field, range 0 to 32. Read as zero when Tx Queue operation is configured (MCAN_TXBC[30] TFQM = 1h). Note: In case of mixed configurations where dedicated Tx Buffers are combined with a Tx FIFO or a Tx Queue, the Put and Get Indices indicate the number of the Tx Buffer starting with the first dedicated Tx Buffers. Reset Source: hsrst_n
0xC8 mcan_core_TXESC rw — Configure data field size for frame transmission
  [2:0] TBDS — Tx Buffer Data Field SizeNote: In case the data length code DLC of a Tx Buffer element is configured to a value higher than the Tx Buffer data field size MCAN_TXESC[2-0] TBDS, the bytes not defined by the Tx Buffer are transmitted as CCh (padding bytes). 0h 8 byte data field1h 12 byte data field2h 16 byte data field3h 20 byte data field4h 24 byte data field5h 32 byte data field6h 48 byte data field7h 64 byte data field
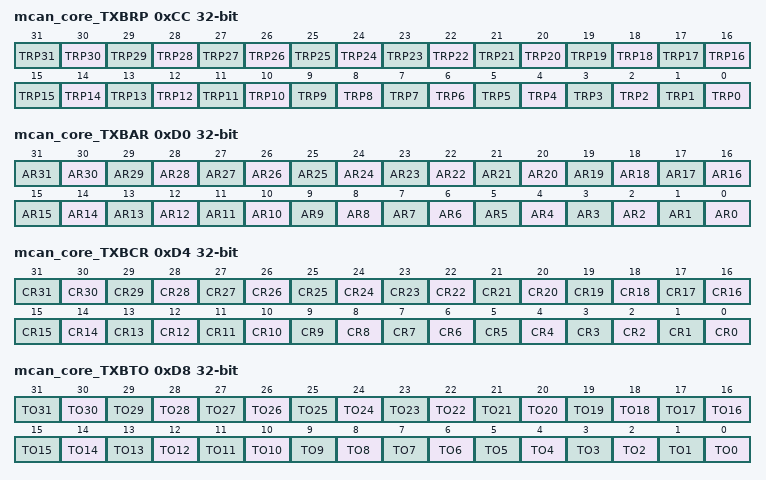
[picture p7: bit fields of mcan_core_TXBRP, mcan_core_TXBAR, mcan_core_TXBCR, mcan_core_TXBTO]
0xCC mcan_core_TXBRP ro — Tx buffers with pending transmission request
  [n] TRP{n} (n=0..31) — Transmission Request Pending 0h No transmission request pending1h Transmission request pending
0xD0 mcan_core_TXBAR — Add transmission requests
  [n] AR{n} (n=0..31) — Add Request 0h No transmission request added1h Transmission requested added (access R/W1TC)
0xD4 mcan_core_TXBCR — Request cancellation of pending transmissions
  [n] CR{n} (n=0..31) — Cancellation Request 0h No cancellation pending1h Cancellation pending (access R/W1TC)
0xD8 mcan_core_TXBTO ro — Signals successful transmissions, set when corresponding TXBRP flag is cleared
  [n] TO{n} (n=0..31) — Transmission Occurred 0h No transmission occurred1h Transmission occurred
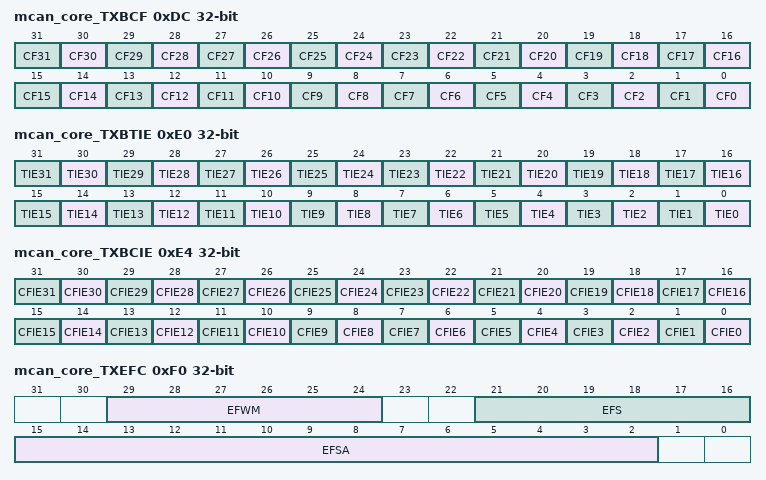
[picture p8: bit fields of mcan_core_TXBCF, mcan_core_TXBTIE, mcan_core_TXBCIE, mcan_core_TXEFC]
0xDC mcan_core_TXBCF ro — Signals successful transmit cancellation, set when corresponding TXBRP flag is cleared after cancellation request
  [n] CF{n} (n=0..31) — Cancellation Finished 0h No transmit buffer cancellation1h Transmit buffer cancellation finished
0xE0 mcan_core_TXBTIE rw — Enable transmit interrupts for selected Tx buffers
  [n] TIE{n} (n=0..31) — Transmission Interrupt Enable 0h Transmission interrupt disabled1h Transmission interrupt enable
0xE4 mcan_core_TXBCIE rw — Enable cancellation finished interrupts for selected Tx buffers
  [n] CFIE{n} (n=0..31) — Cancellation Finished Interrupt Enable 0h Cancellation finished interrupt disabled1h Cancellation finished interrupt enabled
0xE8 mcan_core_reserved1414 reset not defined — Reserved Field
0xEC mcan_core_reserved1515 reset not defined — Reserved Field
0xF0 mcan_core_TXEFC rw — Tx event FIFO watermark, size and start address
  [29:24] EFWM — Event FIFO Watermark 0h Watermark interrupt disabled1h-20 Level for Tx Event FIFO watermark interrupth (MCAN_IR[13] TEFW)>20h Watermark interrupt disabled
  [21:16] EFS — Event FIFO Size 0h Tx Event FIFO disabled1h-20 Number of Tx Event FIFO elementsh>20h Values greater than 32 are interpreted as 32 The Tx Event FIFO elements are indexed from 0 to MCAN_TXEFC[21-16] EFS field - 1.
  [15:2] EFSA — Event FIFO Start Address Start address of Tx Event FIFO in Message RAM (32-bit word address, see Message RAM Configuration). Reset Source: hsrst_n
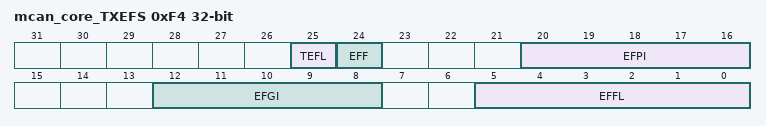
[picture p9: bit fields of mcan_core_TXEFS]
0xF4 mcan_core_TXEFS ro — Tx event FIFO element lost/full indication, put index, get index, and fill level
  [25] TEFL — This bit is a copy of interrupt flag MCAN_IR[15] TEFL. When the MCAN_IR[15] TEFL flag is reset, this bit is also reset. 0h No Tx Event FIFO element lost1h Tx Event FIFO element lost, also set after write attempt to Tx Event FIFO of size zero.
  [24] EFF — Event FIFO Full 0h Tx Event FIFO not full1h Tx Event FIFO full
  [20:16] EFPI — Event FIFO Put Index Tx Event FIFO write index pointer, range 0 to 31. Reset Source: hsrst_n
  [12:8] EFGI — Event FIFO Get Index Tx Event FIFO read index pointer, range 0 to 31. Reset Source: hsrst_n
  [5:0] EFFL — Event FIFO Fill Level Number of elements stored in Tx Event FIFO, range 0 to 32. Reset Source: hsrst_n
0xF8 mcan_core_TXEFA rw — Tx event FIFO acknowledge last index of read elements, updates get index and fill level
  [4:0] EFAI — After the Host CPU has read an element or a sequence of elements from the Tx Event FIFO it has to write the index of the last element read from Tx Event FIFO to the MCAN_TXEFA[4-0] EFAI field. This will set the Tx Event FIFO Get Index MCAN_TXEFS[12-8] EFGI field to the MCAN_TXEFA[4-0] EFAI field + 1 and update the Event FIFO Fill Level MCAN_TXEFS[5-0] EFFL field. Reset Source: hsrst_n
0xFC mcan_core_reserved1616 reset not defined — Reserved Field
0x100 mcan_core_ReservUpper256_j reset not defined — Reserved Field
